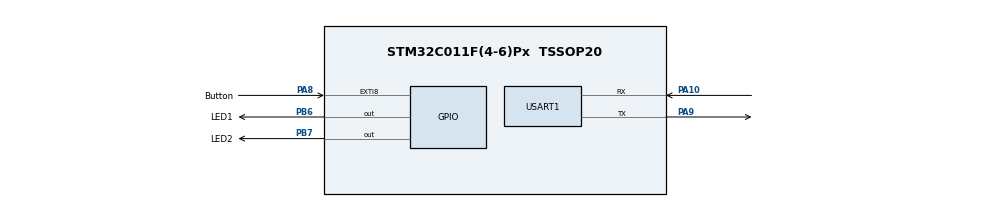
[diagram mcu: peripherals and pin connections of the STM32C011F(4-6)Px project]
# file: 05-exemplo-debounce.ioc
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Mcu.Family=STM32C0
Mcu.Name=STM32C011F(4-6)Px
Mcu.Package=TSSOP20
NVIC.EXTI4_15_IRQn=true\:0\:0\:false\:true\:true\:1\:true\:true\:true
NVIC.TIM17_IRQn=true\:0\:0\:false\:true\:true\:2\:true\:true\:true
PA10\ [PA12].Mode=Asynchronous
PA10\ [PA12].Signal=USART1_RX
PA13.Mode=Serial_Wire
PA13.Signal=DEBUG_SWDIO
PA14-BOOT0.Mode=Serial_Wire
PA14-BOOT0.Signal=DEBUG_SWCLK
PA8.GPIO_Label=Button
PA8.GPIO_ModeDefaultEXTI=GPIO_MODE_IT_RISING_FALLING
PA8.GPIO_PuPd=GPIO_PULLUP
PA8.Signal=GPXTI8
PA9\ [PA11].Mode=Asynchronous
PA9\ [PA11].Signal=USART1_TX
PB6.GPIO_Label=LED1
PB6.Signal=GPIO_Output
PB7.GPIO_Label=LED2
PB7.Signal=GPIO_Output
ProjectManager.HeapSize=0x200
ProjectManager.StackSize=0x400
ProjectManager.TargetToolchain=STM32CubeIDE
RCC.ADCFreq_Value=48000000
RCC.AHBFreq_Value=48000000
RCC.CortexFreq_Value=48000000
RCC.EXTERNAL_CLOCK_VALUE=12288000
RCC.HCLKFreq_Value=48000000
RCC.HSE_VALUE=8000000
RCC.HSISYSCLKDivider=RCC_HSI_DIV1
RCC.HSI_VALUE=48000000
RCC.LSE_VALUE=32768
RCC.SYSCLKFreq_VALUE=48000000
TIM17.Period=(1000 - 1)
TIM17.Prescaler=(48 - 1)
USART1.VirtualMode-Asynchronous=VM_ASYNC
VP_SYS_VS_PINREMAP.Mode=PINREMAP
VP_SYS_VS_PINREMAP_10_12.Mode=PINREMAP_10_12
VP_TIM17_VS_ClockSourceINT.Mode=Enable_Timer
board=custom

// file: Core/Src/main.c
/* USER CODE BEGIN Header */
/**
  ******************************************************************************
  * @file           : main.c
  * @brief          : Main program body
  ******************************************************************************
  * @attention
  *
  * Copyright (c) 2023 STMicroelectronics.
  * All rights reserved.
  *
  * This software is licensed under terms that can be found in the LICENSE file
  * in the root directory of this software component.
  * If no LICENSE file comes with this software, it is provided AS-IS.
  *
  ******************************************************************************
  */
/* USER CODE END Header */
#include "main.h"
#include "tim.h"
#include "usart.h"
#include "gpio.h"

/* USER CODE BEGIN Includes */

#include "isr.h"	// Biblioteca para tratamento de interrupções (externa e de timer)

/* USER CODE END Includes */

void SystemClock_Config(void);
static void MX_NVIC_Init(void);

int main(void)
{
  /* USER CODE BEGIN 1 */

	const uint8_t msg_pressed [] = "Botao pressionado! \r\n";
	const uint8_t msg_released[] = "Botao solto! \r\n";

  /* USER CODE END 1 */

  /* MCU Configuration--------------------------------------------------------*/

  /* Reset of all peripherals, Initializes the Flash interface and the Systick. */
  HAL_Init();

  /* Configure the system clock */
  SystemClock_Config();

  /* Initialize all configured peripherals */
  MX_GPIO_Init();
  MX_TIM17_Init();
  MX_USART1_UART_Init();

  /* Initialize interrupts */
  MX_NVIC_Init();

  /* Infinite loop */
  /* USER CODE BEGIN WHILE */
  while (1)
  {

	  if (debouncedButtonPressed)	// Quando botão é pressionado...
	  {
		  debouncedButtonPressed = 0;
		  HAL_GPIO_TogglePin(LED2_GPIO_Port, LED2_Pin);	// Altera estado do LED2
		  HAL_UART_Transmit(&huart1, msg_pressed, (sizeof(msg_pressed)-1), 1000);	// Transmite mensagem serial pela UART
	  }

	  if (debouncedButtonReleased)	// Quando botão é solto...
	  {
		  debouncedButtonReleased = 0;
		  HAL_UART_Transmit(&huart1, msg_released, (sizeof(msg_released)-1), 1000);	// Transmite mensagem serial pela UART
	  }

    /* USER CODE END WHILE */

  }
}

void SystemClock_Config(void)
{
  RCC_OscInitTypeDef RCC_OscInitStruct = {0};
  RCC_ClkInitTypeDef RCC_ClkInitStruct = {0};

  /** Initializes the RCC Oscillators according to the specified parameters
  * in the RCC_OscInitTypeDef structure.
  */
  RCC_OscInitStruct.OscillatorType = RCC_OSCILLATORTYPE_HSI;
  RCC_OscInitStruct.HSIState = RCC_HSI_ON;
  RCC_OscInitStruct.HSIDiv = RCC_HSI_DIV1;
  RCC_OscInitStruct.HSICalibrationValue = RCC_HSICALIBRATION_DEFAULT;
  if (HAL_RCC_OscConfig(&RCC_OscInitStruct) != HAL_OK)
  {
    Error_Handler();
  }

  /** Initializes the CPU, AHB and APB buses clocks
  */
  RCC_ClkInitStruct.ClockType = RCC_CLOCKTYPE_HCLK|RCC_CLOCKTYPE_SYSCLK
                              |RCC_CLOCKTYPE_PCLK1;
  RCC_ClkInitStruct.SYSCLKSource = RCC_SYSCLKSOURCE_HSI;
  RCC_ClkInitStruct.SYSCLKDivider = RCC_SYSCLK_DIV1;
  RCC_ClkInitStruct.AHBCLKDivider = RCC_HCLK_DIV1;
  RCC_ClkInitStruct.APB1CLKDivider = RCC_APB1_DIV1;

  if (HAL_RCC_ClockConfig(&RCC_ClkInitStruct, FLASH_LATENCY_1) != HAL_OK)
  {
    Error_Handler();
  }
}

/**
  * @brief NVIC Configuration.
  * @retval None
  */
static void MX_NVIC_Init(void)
{
  /* EXTI4_15_IRQn interrupt configuration */
  HAL_NVIC_SetPriority(EXTI4_15_IRQn, 0, 0);
  HAL_NVIC_EnableIRQ(EXTI4_15_IRQn);
  /* TIM17_IRQn interrupt configuration */
  HAL_NVIC_SetPriority(TIM17_IRQn, 0, 0);
  HAL_NVIC_EnableIRQ(TIM17_IRQn);
}

void Error_Handler(void)
{
  __disable_irq();
  while (1)
  {
  }
}
